# SIM3C166_B register map
File version: 1
CPU: 
Registers are 32-bit, read-write, reset 0x0 unless marked. A register's access mark holds for its fields unless they carry their own. Offsets are from the block's base; [hi:lo] are bit positions; 'fields as' and 'values as' point back to an identical list.

## PCA_0
Base 0x4000F000
Same registers: PCA_1 0x40010000
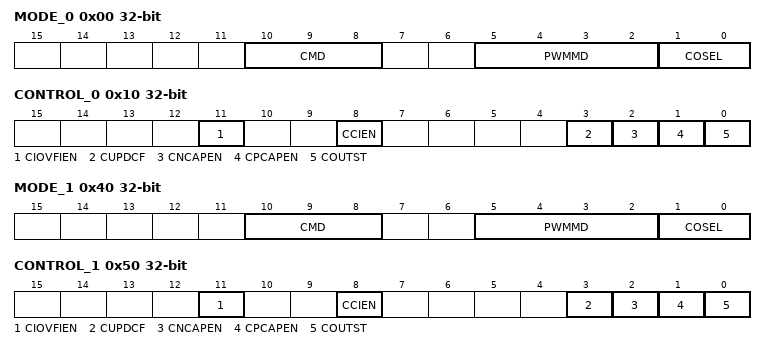
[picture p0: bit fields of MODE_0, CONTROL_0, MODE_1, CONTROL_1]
0x00 MODE_0 — Channel Capture/Compare Mode
  [10:8] CMD — Channel Operating Mode.
    0=EDGE_PWM (Configure the channel for edge-aligned PWM mode.); 1=CENTER_ALIGNED_PWM (Configure the channel for center-aligned PWM mode.); 2=HF_SQUARE_WAVE (Configure the channel for high-frequency/square-wave mode.); 3=TIMER_CAPTURE (Configure the channel for timer/capture mode.); 4=N_BIT_PWM (Configure the channel for n-bit edge-aligned PWM mode.)
  [5:2] PWMMD — PWM N-Bit Mode.
  [1:0] COSEL — Channel Output Function Select.
    0=TOGGLE_OUTPUT (Toggle the channel output at the next capture/compare, overflow, or intermediate event.); 1=SET_OUTPUT (Set the channel output at the next capture/compare, overflow, or intermediate event.); 2=CLEAR_OUTPUT (Clear the output at the next capture/compare, overflow, or intermediate event.); 3=NO_CHANGE (Capture/Compare, overflow, or intermediate events do not control the output state.)
0x10 CONTROL_0 — Channel Capture/Compare Control
  [11] CIOVFIEN — Intermediate Overflow Interrupt Enable.
    0=DISABLED (Disable the channel intermediate overflow interrupt.); 1=ENABLED (Enable the channel intermediate overflow interrupt.)
  [8] CCIEN — Capture/Compare Interrupt Enable.
    0=DISABLED (Disable the channel capture/compare interrupt.); 1=ENABLED (Enable the channel capture/compare interrupt.)
  [3] CUPDCF — Channel Register Update Complete Flag.
    0=NOT_SET (A PCA channel register update completed or is not pending.); 1=SET (A PCA channel register update has not completed and is still pending.)
  [2] CNCAPEN — Negative Edge Input Capture Enable.
    0=DISABLED (Disable negative-edge input capture.); 1=ENABLED (Enable negative-edge input capture.)
  [1] CPCAPEN — Positive Edge Input Capture Enable.
    0=DISABLED (Disable positive-edge input capture.); 1=ENABLED (Enable positive-edge input capture.)
  [0] COUTST — Channel Output State.
    0=LOW (The channel output state is low.); 1=HIGH (The channel output state is high.)
0x20 CCAPV_0 — Channel Compare Value
  [17:0] CCAPV — Channel Compare Value.
0x30 CCAPVUPD_0 — Channel Compare Update Value
  [17:0] CCAPVUPD — Channel Compare Update Value.
0x40 MODE_1 — Channel Capture/Compare Mode
  fields as MODE_0
0x50 CONTROL_1 — Channel Capture/Compare Control
  fields as CONTROL_0
0x60 CCAPV_1 — Channel Compare Value
  [17:0] CCAPV — Channel Compare Value.
0x70 CCAPVUPD_1 — Channel Compare Update Value
  [17:0] CCAPVUPD — Channel Compare Update Value.
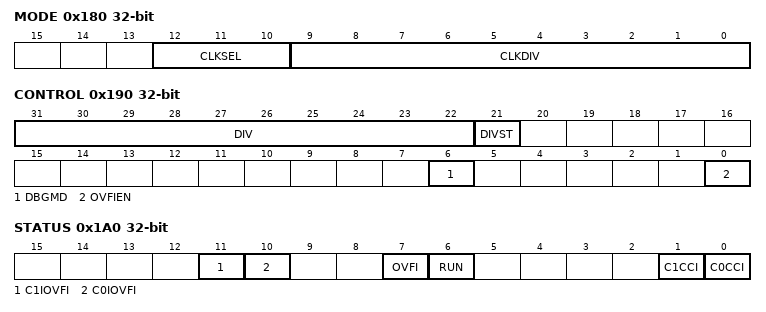
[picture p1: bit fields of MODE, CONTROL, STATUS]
0x180 MODE — Module Operating Mode
  [12:10] CLKSEL — Input Clock (F<subscript>CLKIN</subscript>) Select.
    0=APB (Set the APB as the input clock (FCLKIN).); 1=TIMER0 (Set Timer 0 low overflows divided by 2 as the input clock (FCLKIN).); 2=HL_ECI (Set high-to-low transitions on ECI divided by 2 as the input clock (FCLKIN).); 3=EXTOSCN (Set the external oscillator module output (EXTOSCn) divided by 2 as the input clock (FCLKIN).); 4=ECI (Set ECI transitions divided by 2 as the input clock (FCLKIN).)
  [9:0] CLKDIV — Input Clock Divisor.
0x190 CONTROL — Module Control
  [31:22] DIV — Current Clock Divider Count.
  [21] DIVST — Clock Divider Output State.
    0=OUTPUT_HIGH (The clock divider is currently in the first half-cycle.); 1=OUTPUT_LOW (The clock divider is currently in the second half-cycle.)
  [6] DBGMD — PCA Debug Mode.
    0=HALT (A debug breakpoint will cause the PCA to halt.); 1=RUN (The PCA will continue to operate while the core is halted in debug mode.)
  [0] OVFIEN — PCA Counter Overflow/Limit Interrupt Enable.
    0=DISABLED (Disable the PCA counter overflow/limit event interrupt.); 1=ENABLED (Enable the PCA counter overflow/limit event interrupt.)
0x1A0 STATUS — Module Status
  [11] C1IOVFI — Channel 1 Intermediate Overflow Interrupt Flag.
    0=NOT_SET (Channel 1 did not count past the channel n-bit mode limit.); 1=SET (Channel 1 counted past the channel n-bit mode limit.)
  [10] C0IOVFI — Channel 0 Intermediate Overflow Interrupt Flag.
    0=NOT_SET (Channel 0 did not count past the channel n-bit mode limit.); 1=SET (Channel 0 counted past the channel n-bit mode limit.)
  [7] OVFI — Counter/Timer Overflow/Limit Interrupt Flag.
    0=NOT_SET (A PCA Counter/Timer overflow/limit event did not occur.); 1=SET (A PCA Counter/Timer overflow/limit event occurred.)
  [6] RUN — Counter/Timer Run.
    0=STOP (Stop the PCA Counter/Timer.); 1=START (Start the PCA Counter/Timer.)
  [1] C1CCI — Channel 1 Capture/Compare Interrupt Flag.
    0=NOT_SET (A Channel 1 match or capture event did not occur.); 1=SET (A Channel 1 match or capture event occurred.)
  [0] C0CCI — Channel 0 Capture/Compare Interrupt Flag.
    0=NOT_SET (A Channel 0 match or capture event did not occur.); 1=SET (A Channel 0 match or capture event occurred.)
0x1B0 COUNTER — Module Counter/Timer
  [15:0] COUNTER — Counter/Timer.
0x1C0 LIMIT reset 0xFFFF — Module Counter/Timer Upper Limit
  [15:0] LIMIT — Upper Limit.
